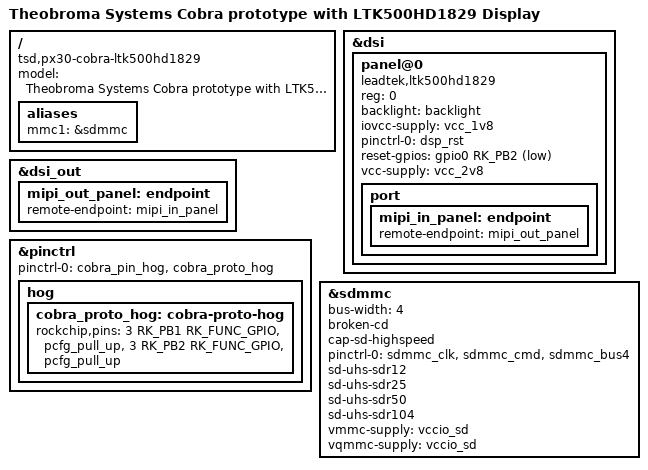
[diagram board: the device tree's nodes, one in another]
// SPDX-License-Identifier: (GPL-2.0+ OR MIT)
/*
 * Copyright (c) 2025 Cherry Embedded Solutions GmbH
 */

/dts-v1/;
#include "px30-cobra.dtsi"

/ {
	model = "Theobroma Systems Cobra prototype with LTK500HD1829 Display";
	compatible = "tsd,px30-cobra-ltk500hd1829", "tsd,px30-cobra", "rockchip,px30";

	aliases {
		mmc1 = &sdmmc;
	};
};

&dsi {
	#address-cells = <1>;
	#size-cells = <0>;
	status = "okay";

	panel@0 {
		compatible = "leadtek,ltk500hd1829";
		reg = <0>;
		backlight = <&backlight>;
		iovcc-supply = <&vcc_1v8>;
		pinctrl-names = "default";
		pinctrl-0 = <&dsp_rst>;
		reset-gpios = <&gpio0 RK_PB2 GPIO_ACTIVE_LOW>;
		vcc-supply = <&vcc_2v8>;

		port {
			mipi_in_panel: endpoint {
				remote-endpoint = <&mipi_out_panel>;
			};
		};
	};
};

&dsi_out {
	mipi_out_panel: endpoint {
		remote-endpoint = <&mipi_in_panel>;
	};
};

&pinctrl {
	pinctrl-names = "default";
	pinctrl-0 = <&cobra_pin_hog>, <&cobra_proto_hog>;

	hog {
		cobra_proto_hog: cobra-proto-hog {
			rockchip,pins =
				/* STUSB4500 open drain outout POWER_OK2, needs pull-up */
				<3 RK_PB1 RK_FUNC_GPIO &pcfg_pull_up>,
				/* STUSB4500 open drain outout POWER_OK3, needs pull-up */
				<3 RK_PB2 RK_FUNC_GPIO &pcfg_pull_up>;
		};
	};
};

&sdmmc {
	bus-width = <4>;
	broken-cd;
	cap-sd-highspeed;
	pinctrl-names = "default";
	pinctrl-0 = <&sdmmc_clk &sdmmc_cmd &sdmmc_bus4>;
	sd-uhs-sdr12;
	sd-uhs-sdr25;
	sd-uhs-sdr50;
	sd-uhs-sdr104;
	vmmc-supply = <&vccio_sd>;
	vqmmc-supply = <&vccio_sd>;
	status = "okay";
};
